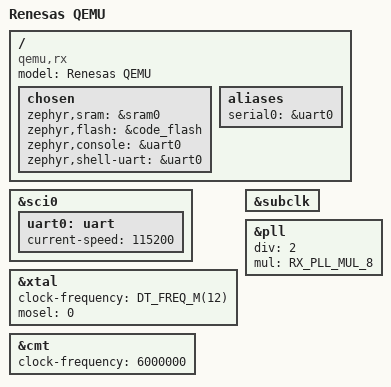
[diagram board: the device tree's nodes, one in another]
/*
 * Copyright (c) 2024 Renesas Electronics Corporation
 *
 * SPDX-License-Identifier: Apache-2.0
 */

/dts-v1/;

#include <renesas/rx-qemu.dtsi>
#include <dt-bindings/gpio/gpio.h>

/ {
	model = "Renesas QEMU";
	compatible = "qemu,rx";

	chosen {
		zephyr,sram = &sram0;
		zephyr,flash = &code_flash;
		zephyr,console = &uart0;
		zephyr,shell-uart = &uart0;
	};

	aliases {
		serial0 = &uart0;
	};
};

&sci0 {
	status = "okay";

	uart0: uart {
		current-speed = <115200>;
		status = "okay";
	};
};

&xtal {
	clock-frequency = <DT_FREQ_M(12)>;
	mosel = <0>;
	#clock-cells = <0>;
	status = "okay";
};

&subclk {
	status = "okay";
};

&pll {
	div = <2>;
	mul = <RX_PLL_MUL_8>;
	status = "okay";
};

&cmt {
	clock-frequency = <6000000>;
	status = "okay";
};
